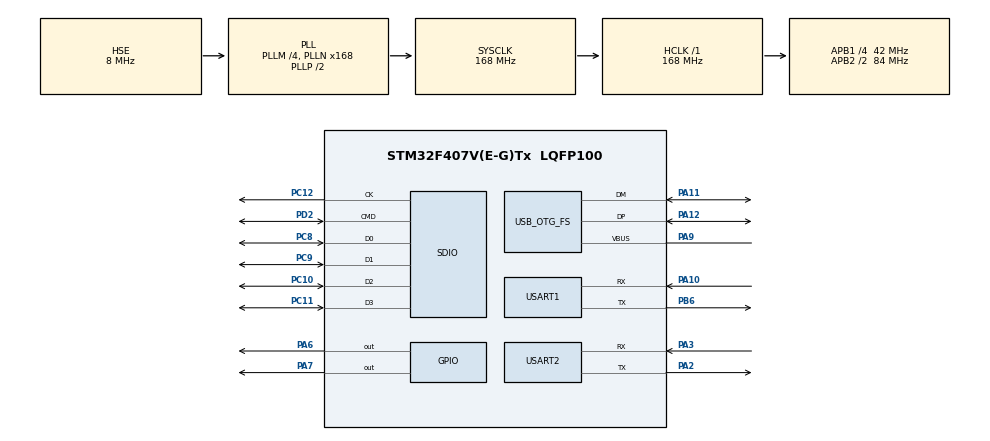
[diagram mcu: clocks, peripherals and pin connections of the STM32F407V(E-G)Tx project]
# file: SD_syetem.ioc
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FATFS._MAX_SS=4096
Mcu.Family=STM32F4
Mcu.Name=STM32F407V(E-G)Tx
Mcu.Package=LQFP100
NVIC.OTG_FS_IRQn=true\:0\:0\:false\:false\:true\:true\:true\:true
NVIC.PriorityGroup=NVIC_PRIORITYGROUP_4
NVIC.USART1_IRQn=true\:0\:0\:false\:false\:true\:true\:true\:true
NVIC.USART2_IRQn=true\:0\:0\:false\:false\:true\:true\:true\:true
PA10.Mode=Asynchronous
PA10.Signal=USART1_RX
PA11.Mode=Device_Only
PA11.Signal=USB_OTG_FS_DM
PA12.Mode=Device_Only
PA12.Signal=USB_OTG_FS_DP
PA13.Mode=Serial_Wire
PA13.Signal=SYS_JTMS-SWDIO
PA14.Mode=Serial_Wire
PA14.Signal=SYS_JTCK-SWCLK
PA2.Mode=Asynchronous
PA2.Signal=USART2_TX
PA3.Mode=Asynchronous
PA3.Signal=USART2_RX
PA6.Signal=GPIO_Output
PA7.Signal=GPIO_Output
PA9.Mode=Activate_VBUS
PA9.Signal=USB_OTG_FS_VBUS
PB6.Mode=Asynchronous
PB6.Signal=USART1_TX
PC10.Mode=SD_4_bits_Wide_bus
PC10.Signal=SDIO_D2
PC11.Mode=SD_4_bits_Wide_bus
PC11.Signal=SDIO_D3
PC12.Mode=SD_4_bits_Wide_bus
PC12.Signal=SDIO_CK
PC8.Mode=SD_4_bits_Wide_bus
PC8.Signal=SDIO_D0
PC9.Mode=SD_4_bits_Wide_bus
PC9.Signal=SDIO_D1
PD2.Mode=SD_4_bits_Wide_bus
PD2.Signal=SDIO_CMD
PH0-OSC_IN.Mode=HSE-External-Oscillator
PH0-OSC_IN.Signal=RCC_OSC_IN
PH1-OSC_OUT.Mode=HSE-External-Oscillator
PH1-OSC_OUT.Signal=RCC_OSC_OUT
ProjectManager.HeapSize=0x200
ProjectManager.StackSize=0x400
ProjectManager.TargetToolchain=STM32CubeIDE
RCC.48MHZClocksFreq_Value=48000000
RCC.AHBFreq_Value=168000000
RCC.APB1CLKDivider=RCC_HCLK_DIV4
RCC.APB1Freq_Value=42000000
RCC.APB1TimFreq_Value=84000000
RCC.APB2CLKDivider=RCC_HCLK_DIV2
RCC.APB2Freq_Value=84000000
RCC.APB2TimFreq_Value=168000000
RCC.CortexFreq_Value=168000000
RCC.HCLKFreq_Value=168000000
RCC.HSE_VALUE=8000000
RCC.HSI_VALUE=16000000
RCC.LSE_VALUE=32768
RCC.PLLM=4
RCC.PLLN=168
RCC.PLLQ=7
RCC.SYSCLKFreq_VALUE=168000000
RCC.SYSCLKSource=RCC_SYSCLKSOURCE_PLLCLK
RCC.VCOOutputFreq_Value=336000000
USART1.VirtualMode=VM_ASYNC
USART2.VirtualMode=VM_ASYNC
USB_OTG_FS.VirtualMode=Device_Only
VP_FATFS_VS_SDIO.Mode=SDIO
board=custom

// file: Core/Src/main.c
/* USER CODE BEGIN Header */
/**
  ******************************************************************************
  * @file           : main.c
  * @brief          : Main program body
  ******************************************************************************
  * @attention
  *
  * Copyright (c) 2023 STMicroelectronics.
  * All rights reserved.
  *
  * This software is licensed under terms that can be found in the LICENSE file
  * in the root directory of this software component.
  * If no LICENSE file comes with this software, it is provided AS-IS.
  *
  ******************************************************************************
  */
/* USER CODE END Header */
#include "main.h"
#include "fatfs.h"

/* USER CODE BEGIN Includes */
#include "file_handling.h"
#include "UartRingbuffer.h"
/* USER CODE END Includes */

 SD_HandleTypeDef hsd;

UART_HandleTypeDef huart1;
UART_HandleTypeDef huart2;

PCD_HandleTypeDef hpcd_USB_OTG_FS;

void SystemClock_Config(void);
static void MX_GPIO_Init(void);
static void MX_SDIO_SD_Init(void);
static void MX_USART1_UART_Init(void);
static void MX_USART2_UART_Init(void);
static void MX_USB_OTG_FS_PCD_Init(void);

/* USER CODE BEGIN 0 */
char cmd=0;
/* USER CODE END 0 */

int main(void)
{

  /* MCU Configuration--------------------------------------------------------*/

  /* Reset of all peripherals, Initializes the Flash interface and the Systick. */
  HAL_Init();

  /* Configure the system clock */
  SystemClock_Config();

  /* Initialize all configured peripherals */
  MX_GPIO_Init();
  MX_SDIO_SD_Init();
  MX_USART1_UART_Init();
  MX_FATFS_Init();
  MX_USART2_UART_Init();
  MX_USB_OTG_FS_PCD_Init();
  /* USER CODE BEGIN 2 */
  Ringbuf_init();
  mount_sd();
  /* USER CODE END 2 */

  /* Infinite loop */

  while (1)
  {
	  HAL_GPIO_TogglePin(GPIOA, GPIO_PIN_6|GPIO_PIN_7);
	  HAL_Delay(100);
    while(IsDataAvailable())
    {
    	HAL_GPIO_WritePin(GPIOA, GPIO_PIN_7, GPIO_PIN_SET);
    	Get_string(buffer);
    	int len= cmdlength(buffer);
    	get_path();

    	if(!(strncmp("ls",buffer,len)))cmd='l';
    	if(!(strncmp("mkdir",buffer,len)))cmd='m';
    	if(!(strncmp("mkfil",buffer,len)))cmd='c';
    	if(!(strncmp("read",buffer,len)))cmd='r';
    	if(!(strncmp("write",buffer,len)))cmd='w';
    	if(!(strncmp("rm",buffer,len)))cmd='d';
    	if(!(strncmp("update",buffer,len)))cmd='u';
    	if(!(strncmp("checkfile",buffer,len)))cmd='f';
    	if(!(strncmp("checksd",buffer,len)))cmd='s';

    	switch (cmd)
    	{
		case ('l'):
		HAL_GPIO_TogglePin(GPIOA, GPIO_PIN_6|GPIO_PIN_7);
		HAL_Delay(20);
		HAL_GPIO_TogglePin(GPIOA, GPIO_PIN_6|GPIO_PIN_7);
				scan_files(path);
				cmd=0;
				clear_path();
				clear_buffer();
				break;
		case ('m'):
		HAL_GPIO_TogglePin(GPIOA, GPIO_PIN_6);
				HAL_Delay(20);
				HAL_GPIO_TogglePin(GPIOA, GPIO_PIN_6);
				create_dir(path);
				cmd=0;
				clear_path();
						break;
		case ('c'):
		HAL_GPIO_TogglePin(GPIOA, GPIO_PIN_6);
				HAL_Delay(20);
				HAL_GPIO_TogglePin(GPIOA, GPIO_PIN_6);
				        create_dir(path);
						cmd=0;
						clear_path();
						break;
		case ('r'):
		HAL_GPIO_TogglePin(GPIOA, GPIO_PIN_6);
						HAL_Delay(20);
						HAL_GPIO_TogglePin(GPIOA, GPIO_PIN_6);

				        read_file(path);
						cmd=0;
			     		clear_path();
						break;
		case ('w'):
		HAL_GPIO_TogglePin(GPIOA, GPIO_PIN_6);
						HAL_Delay(20);
						HAL_GPIO_TogglePin(GPIOA, GPIO_PIN_6);
				write_file(path);
								cmd=0;
								clear_path();
						break;

		case ('d'):
		HAL_GPIO_TogglePin(GPIOA, GPIO_PIN_6);
						HAL_Delay(20);
						HAL_GPIO_TogglePin(GPIOA, GPIO_PIN_6);

                        remove_file(path);
		                cmd=0;
						clear_path();
						break;
		case ('u'):
		HAL_GPIO_TogglePin(GPIOA, GPIO_PIN_6);
						HAL_Delay(20);
						HAL_GPIO_TogglePin(GPIOA, GPIO_PIN_6);

	                    update_file(path);
		                cmd=0;
						clear_path();
						break;
		case ('f'):
		HAL_GPIO_TogglePin(GPIOA, GPIO_PIN_6);
						HAL_Delay(20);
						HAL_GPIO_TogglePin(GPIOA, GPIO_PIN_6);

						check_file(path);
		                cmd=0;
						clear_path();
						break;
		case ('s'):
				HAL_GPIO_TogglePin(GPIOA, GPIO_PIN_6);
		HAL_Delay(20);
		HAL_GPIO_TogglePin(GPIOA, GPIO_PIN_6);

						check_sd();
	                	cmd=0;
						clear_path();
						break;

		default:
			clear_buffer();
			clear_path();
			break;

    	}
    }
  }

}

void SystemClock_Config(void)
{
  RCC_OscInitTypeDef RCC_OscInitStruct = {0};
  RCC_ClkInitTypeDef RCC_ClkInitStruct = {0};

  /** Configure the main internal regulator output voltage
  */
  __HAL_RCC_PWR_CLK_ENABLE();
  __HAL_PWR_VOLTAGESCALING_CONFIG(PWR_REGULATOR_VOLTAGE_SCALE1);

  /** Initializes the RCC Oscillators according to the specified parameters
  * in the RCC_OscInitTypeDef structure.
  */
  RCC_OscInitStruct.OscillatorType = RCC_OSCILLATORTYPE_HSE;
  RCC_OscInitStruct.HSEState = RCC_HSE_ON;
  RCC_OscInitStruct.PLL.PLLState = RCC_PLL_ON;
  RCC_OscInitStruct.PLL.PLLSource = RCC_PLLSOURCE_HSE;
  RCC_OscInitStruct.PLL.PLLM = 4;
  RCC_OscInitStruct.PLL.PLLN = 168;
  RCC_OscInitStruct.PLL.PLLP = RCC_PLLP_DIV2;
  RCC_OscInitStruct.PLL.PLLQ = 7;
  if (HAL_RCC_OscConfig(&RCC_OscInitStruct) != HAL_OK)
  {
    Error_Handler();
  }

  /** Initializes the CPU, AHB and APB buses clocks
  */
  RCC_ClkInitStruct.ClockType = RCC_CLOCKTYPE_HCLK|RCC_CLOCKTYPE_SYSCLK
                              |RCC_CLOCKTYPE_PCLK1|RCC_CLOCKTYPE_PCLK2;
  RCC_ClkInitStruct.SYSCLKSource = RCC_SYSCLKSOURCE_PLLCLK;
  RCC_ClkInitStruct.AHBCLKDivider = RCC_SYSCLK_DIV1;
  RCC_ClkInitStruct.APB1CLKDivider = RCC_HCLK_DIV4;
  RCC_ClkInitStruct.APB2CLKDivider = RCC_HCLK_DIV2;

  if (HAL_RCC_ClockConfig(&RCC_ClkInitStruct, FLASH_LATENCY_5) != HAL_OK)
  {
    Error_Handler();
  }
}

static void MX_SDIO_SD_Init(void)
{

  hsd.Instance = SDIO;
  hsd.Init.ClockEdge = SDIO_CLOCK_EDGE_RISING;
  hsd.Init.ClockBypass = SDIO_CLOCK_BYPASS_DISABLE;
  hsd.Init.ClockPowerSave = SDIO_CLOCK_POWER_SAVE_DISABLE;
  hsd.Init.BusWide = SDIO_BUS_WIDE_1B;
  hsd.Init.HardwareFlowControl = SDIO_HARDWARE_FLOW_CONTROL_DISABLE;
  hsd.Init.ClockDiv = 0;

}

static void MX_USART1_UART_Init(void)
{

  huart1.Instance = USART1;
  huart1.Init.BaudRate = 115200;
  huart1.Init.WordLength = UART_WORDLENGTH_8B;
  huart1.Init.StopBits = UART_STOPBITS_1;
  huart1.Init.Parity = UART_PARITY_NONE;
  huart1.Init.Mode = UART_MODE_TX_RX;
  huart1.Init.HwFlowCtl = UART_HWCONTROL_NONE;
  huart1.Init.OverSampling = UART_OVERSAMPLING_16;
  if (HAL_UART_Init(&huart1) != HAL_OK)
  {
    Error_Handler();
  }

}

static void MX_USART2_UART_Init(void)
{

  huart2.Instance = USART2;
  huart2.Init.BaudRate = 115200;
  huart2.Init.WordLength = UART_WORDLENGTH_8B;
  huart2.Init.StopBits = UART_STOPBITS_1;
  huart2.Init.Parity = UART_PARITY_NONE;
  huart2.Init.Mode = UART_MODE_TX_RX;
  huart2.Init.HwFlowCtl = UART_HWCONTROL_NONE;
  huart2.Init.OverSampling = UART_OVERSAMPLING_16;
  if (HAL_UART_Init(&huart2) != HAL_OK)
  {
    Error_Handler();
  }

}

static void MX_USB_OTG_FS_PCD_Init(void)
{

  hpcd_USB_OTG_FS.Instance = USB_OTG_FS;
  hpcd_USB_OTG_FS.Init.dev_endpoints = 4;
  hpcd_USB_OTG_FS.Init.speed = PCD_SPEED_FULL;
  hpcd_USB_OTG_FS.Init.dma_enable = DISABLE;
  hpcd_USB_OTG_FS.Init.phy_itface = PCD_PHY_EMBEDDED;
  hpcd_USB_OTG_FS.Init.Sof_enable = DISABLE;
  hpcd_USB_OTG_FS.Init.low_power_enable = DISABLE;
  hpcd_USB_OTG_FS.Init.lpm_enable = DISABLE;
  hpcd_USB_OTG_FS.Init.vbus_sensing_enable = ENABLE;
  hpcd_USB_OTG_FS.Init.use_dedicated_ep1 = DISABLE;
  if (HAL_PCD_Init(&hpcd_USB_OTG_FS) != HAL_OK)
  {
    Error_Handler();
  }

}

static void MX_GPIO_Init(void)
{
  GPIO_InitTypeDef GPIO_InitStruct = {0};

  /* GPIO Ports Clock Enable */
  __HAL_RCC_GPIOH_CLK_ENABLE();
  __HAL_RCC_GPIOA_CLK_ENABLE();
  __HAL_RCC_GPIOC_CLK_ENABLE();
  __HAL_RCC_GPIOD_CLK_ENABLE();
  __HAL_RCC_GPIOB_CLK_ENABLE();

  /*Configure GPIO pin Output Level */
  HAL_GPIO_WritePin(GPIOA, GPIO_PIN_6|GPIO_PIN_7, GPIO_PIN_RESET);

  /*Configure GPIO pins : PA6 PA7 */
  GPIO_InitStruct.Pin = GPIO_PIN_6|GPIO_PIN_7;
  GPIO_InitStruct.Mode = GPIO_MODE_OUTPUT_PP;
  GPIO_InitStruct.Pull = GPIO_NOPULL;
  GPIO_InitStruct.Speed = GPIO_SPEED_FREQ_LOW;
  HAL_GPIO_Init(GPIOA, &GPIO_InitStruct);

}

void Error_Handler(void)
{
  __disable_irq();
  while (1)
  {
  }
}
